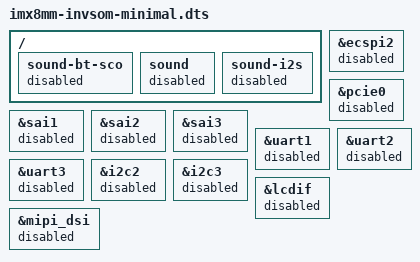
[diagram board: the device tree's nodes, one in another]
// SPDX-License-Identifier: (GPL-2.0+ OR MIT)
/*
 * Copyright 2019 NXP
 */

/dts-v1/;

#include "imx8mm-invsom.dts"

/ {
	sound-bt-sco {
		status = "disabled";
	};
	
	sound {
		status = "disabled";
	};
	
	sound-i2s {
		status = "disabled";
	};
};

&ecspi2 {
	status = "disabled";
};

&pcie0 {
	status = "disabled";
};

&sai1 {
	status = "disabled";
};

&sai2 {
	status = "disabled";
};

&sai3 {
	status = "disabled";
};

&uart1 {
	status = "disabled";
};

&uart2 {
	status = "disabled";
};

&uart3 {
	status = "disabled";
};

&i2c2 {
	status = "disabled";
};

&i2c3 {
	status = "disabled";
};

&lcdif {
	status = "disabled";
};

&mipi_dsi {
	status = "disabled";
};













